# MK22F51212 register map
Vendor: Freescale Semiconductor, Inc.; Series: Kinetis_K; File version: 1.6
CPU: CM4 r0p1, little endian, no MPU, FPU, VTOR, 4 interrupt priority bits
Registers are 32-bit, read-write, reset 0x0 unless marked. A register's access mark holds for its fields unless they carry their own. Offsets are from the block's base; [hi:lo] are bit positions; {n}, {i} and the like mark numbered series.

## PIT — Periodic Interrupt Timer
Base 0x40037000; register names take the prefix PIT_
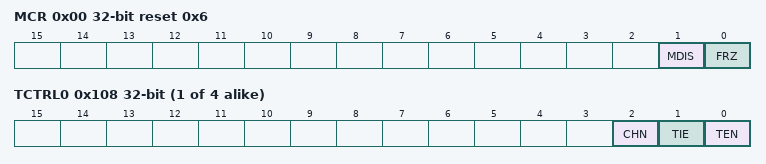
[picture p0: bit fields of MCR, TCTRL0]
0x00 MCR reset 0x6 — PIT Module Control Register
  [1] MDIS — Module Disable - (PIT section)
    0=Clock for standard PIT timers is enabled; 1=Clock for standard PIT timers is disabled
  [0] FRZ — Freeze
    0=Timers continue to run in Debug mode; 1=Timers are stopped in Debug mode
{0x100+0x10*i} LDVAL{i} (i=0..3) — Timer Load Value Register
  [31:0] TSV — Timer Start Value
{0x104+0x10*i} CVAL{i} (i=0..3) ro — Current Timer Value Register
  [31:0] TVL — Current Timer Value
{0x108+0x10*i} TCTRL{i} (i=0..3) — Timer Control Register
  [2] CHN — Chain Mode
    0=Timer is not chained; 1=Timer is chained to previous timer. For example, for Channel 2, if this field is set, Timer 2 is chained to Timer 1.
  [1] TIE — Timer Interrupt Enable
    0=Interrupt requests from Timer n are disabled; 1=Interrupt will be requested whenever TIF is set
  [0] TEN — Timer Enable
    0=Timer n is disabled; 1=Timer n is enabled
{0x10C+0x10*i} TFLG{i} (i=0..3) — Timer Flag Register
  [0] TIF — Timer Interrupt Flag
    0=Timeout has not yet occurred; 1=Timeout has occurred

## RFVBAT — VBAT register file
Base 0x4003E000; register names take the prefix RFVBAT_
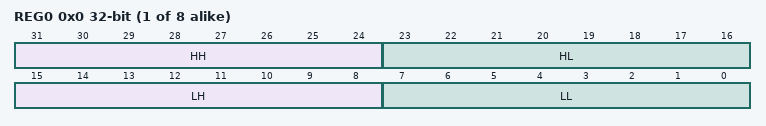
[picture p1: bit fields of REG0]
{0x0+4i} REG{i} (i=0..7) — VBAT register file register
  [31:24] HH — High higher byte
  [23:16] HL — High lower byte
  [15:8] LH — Low higher byte
  [7:0] LL — Low lower byte

## LPTMR0 — Low Power Timer
Base 0x40040000; register names take the prefix LPTMR0_
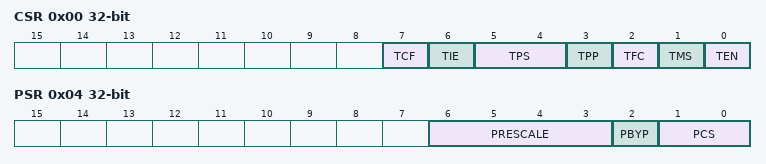
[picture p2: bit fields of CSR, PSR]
0x00 CSR — Low Power Timer Control Status Register
  [7] TCF — Timer Compare Flag
    0=The value of CNR is not equal to CMR and increments; 1=The value of CNR is equal to CMR and increments
  [6] TIE — Timer Interrupt Enable
    0=Timer interrupt disabled; 1=Timer interrupt enabled
  [5:4] TPS — Timer Pin Select
    {v}=Pulse counter input {v} is selected (v=0..3)
  [3] TPP — Timer Pin Polarity
    0=Pulse Counter input source is active-high, and the CNR will increment on the rising-edge; 1=Pulse Counter input source is active-low, and the CNR will increment on the falling-edge
  [2] TFC — Timer Free-Running Counter
    0=CNR is reset whenever TCF is set; 1=CNR is reset on overflow
  [1] TMS — Timer Mode Select
    0=Time Counter mode; 1=Pulse Counter mode
  [0] TEN — Timer Enable
    0=LPTMR is disabled and internal logic is reset; 1=LPTMR is enabled
0x04 PSR — Low Power Timer Prescale Register
  [6:3] PRESCALE — Prescale Value
    0=Prescaler divides the prescaler clock by 2; glitch filter does not support this configuration; 1=Prescaler divides the prescaler clock by 4; glitch filter recognizes change on input pin after 2 rising clock edges; 2=Prescaler divides the prescaler clock by 8; glitch filter recognizes change on input pin after 4 rising clock edges; 3=Prescaler divides the prescaler clock by 16; glitch filter recognizes change on input pin after 8 rising clock edges; 4=Prescaler divides the prescaler clock by 32; glitch filter recognizes change on input pin after 16 rising clock edges; 5=Prescaler divides the prescaler clock by 64; glitch filter recognizes change on input pin after 32 rising clock edges; 6=Prescaler divides the prescaler clock by 128; glitch filter recognizes change on input pin after 64 rising clock edges; 7=Prescaler divides the prescaler clock by 256; glitch filter recognizes change on input pin after 128 rising clock edges; 8=Prescaler divides the prescaler clock by 512; glitch filter recognizes change on input pin after 256 rising clock edges; 9=Prescaler divides the prescaler clock by 1024; glitch filter recognizes change on input pin after 512 rising clock edges; 10=Prescaler divides the prescaler clock by 2048; glitch filter recognizes change on input pin after 1024 rising clock edges; 11=Prescaler divides the prescaler clock by 4096; glitch filter recognizes change on input pin after 2048 rising clock edges; 12=Prescaler divides the prescaler clock by 8192; glitch filter recognizes change on input pin after 4096 rising clock edges; 13=Prescaler divides the prescaler clock by 16,384; glitch filter recognizes change on input pin after 8192 rising clock edges; 14=Prescaler divides the prescaler clock by 32,768; glitch filter recognizes change on input pin after 16,384 rising clock edges; 15=Prescaler divides the prescaler clock by 65,536; glitch filter recognizes change on input pin after 32,768 rising clock edges
  [2] PBYP — Prescaler Bypass
    0=Prescaler/glitch filter is enabled; 1=Prescaler/glitch filter is bypassed
  [1:0] PCS — Prescaler Clock Select
    {v}=Prescaler/glitch filter clock {v} selected (v=0..3)
0x08 CMR — Low Power Timer Compare Register
  [15:0] COMPARE — Compare Value
0x0C CNR — Low Power Timer Counter Register
  [15:0] COUNTER — Counter Value
